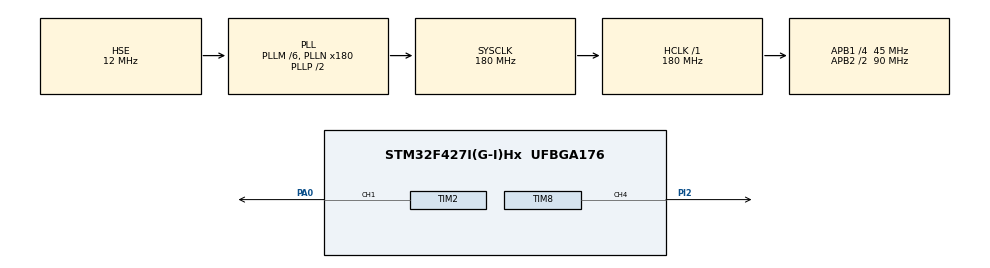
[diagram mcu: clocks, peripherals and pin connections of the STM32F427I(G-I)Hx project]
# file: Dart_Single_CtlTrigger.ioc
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Mcu.Family=STM32F4
Mcu.Name=STM32F427I(G-I)Hx
Mcu.Package=UFBGA176
NVIC.PriorityGroup=NVIC_PRIORITYGROUP_4
NVIC.TIM4_IRQn=true\:15\:0\:false\:false\:true\:false\:true\:true
NVIC.TimeBase=TIM4_IRQn
NVIC.TimeBaseIP=TIM4
PA0/WKUP.Signal=S_TIM2_CH1_ETR
PA13.Mode=Serial_Wire
PA13.Signal=SYS_JTMS-SWDIO
PA14.Mode=Serial_Wire
PA14.Signal=SYS_JTCK-SWCLK
PC14/OSC32_IN.Mode=LSE-External-Oscillator
PC14/OSC32_IN.Signal=RCC_OSC32_IN
PC15/OSC32_OUT.Mode=LSE-External-Oscillator
PC15/OSC32_OUT.Signal=RCC_OSC32_OUT
PH0/OSC_IN.Mode=HSE-External-Oscillator
PH0/OSC_IN.Signal=RCC_OSC_IN
PH1/OSC_OUT.Mode=HSE-External-Oscillator
PH1/OSC_OUT.Signal=RCC_OSC_OUT
PI2.Signal=S_TIM8_CH4
ProjectManager.HeapSize=0x200
ProjectManager.StackSize=0x400
ProjectManager.TargetToolchain=MDK-ARM V5.32
RCC.48MHZClocksFreq_Value=90000000
RCC.AHBFreq_Value=180000000
RCC.APB1CLKDivider=RCC_HCLK_DIV4
RCC.APB1Freq_Value=45000000
RCC.APB1TimFreq_Value=90000000
RCC.APB2CLKDivider=RCC_HCLK_DIV2
RCC.APB2Freq_Value=90000000
RCC.APB2TimFreq_Value=180000000
RCC.CortexFreq_Value=180000000
RCC.HCLKFreq_Value=180000000
RCC.HSE_VALUE=12000000
RCC.HSI_VALUE=16000000
RCC.PLLM=6
RCC.PLLN=180
RCC.PLLSourceVirtual=RCC_PLLSOURCE_HSE
RCC.SYSCLKFreq_VALUE=180000000
RCC.SYSCLKSource=RCC_SYSCLKSOURCE_PLLCLK
RCC.VCOOutputFreq_Value=360000000
SH.S_TIM2_CH1_ETR.0=TIM2_CH1,PWM Generation1 CH1
SH.S_TIM8_CH4.0=TIM8_CH4,PWM Generation4 CH4
TIM2.AutoReloadPreload=TIM_AUTORELOAD_PRELOAD_ENABLE
TIM2.Channel-PWM\ Generation1\ CH1=TIM_CHANNEL_1
TIM2.Period=20000 - 1
TIM2.Prescaler=180 - 1
TIM2.Pulse-PWM\ Generation1\ CH1=2500
TIM8.AutoReloadPreload=TIM_AUTORELOAD_PRELOAD_ENABLE
TIM8.Channel-PWM\ Generation4\ CH4=TIM_CHANNEL_4
TIM8.Period=20000 - 1
TIM8.Prescaler=180 - 1
TIM8.Pulse-PWM\ Generation4\ CH4=500
VP_SYS_VS_tim4.Mode=TIM4
VP_TIM2_VS_ClockSourceINT.Mode=Internal
VP_TIM8_VS_ClockSourceINT.Mode=Internal
board=custom

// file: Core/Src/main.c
/* USER CODE BEGIN Header */
/**
  ******************************************************************************
  * @file           : main.c
  * @brief          : Main program body
  ******************************************************************************
  * @attention
  *
  * Copyright (c) 2026 STMicroelectronics.
  * All rights reserved.
  *
  * This software is licensed under terms that can be found in the LICENSE file
  * in the root directory of this software component.
  * If no LICENSE file comes with this software, it is provided AS-IS.
  *
  ******************************************************************************
  */
/* USER CODE END Header */
#include "main.h"
#include "tim.h"
#include "gpio.h"

void SystemClock_Config(void);

int main(void)
{

  /* MCU Configuration--------------------------------------------------------*/

  /* Reset of all peripherals, Initializes the Flash interface and the Systick. */

  HAL_Init();

  /* Configure the system clock */
  SystemClock_Config();

  /* Initialize all configured peripherals */
  MX_GPIO_Init();
  MX_TIM2_Init();
  MX_TIM8_Init();
  /* USER CODE BEGIN 2 */
	HAL_TIM_Base_Start(&htim8);
  HAL_TIM_PWM_Start(&htim8, TIM_CHANNEL_4);
	HAL_Delay(500);
  // __HAL_TIM_SetCompare(&htim8, TIM_CHANNEL_4, 2500); // 直接复位
	// HAL_Delay(1000);
	// __HAL_TIM_SetCompare(&htim8, TIM_CHANNEL_4, 500);
	// HAL_Delay(2000);
  /* USER CODE END 2 */

  /* Infinite loop */
  /* USER CODE BEGIN WHILE */
	uint16_t a = 500;
	uint16_t b = 1200;
	uint16_t c = 1200;
  while (1)
  {
		a = a + 100;
		__HAL_TIM_SetCompare(&htim8, TIM_CHANNEL_4, b);

	  HAL_Delay(1000);

		__HAL_TIM_SetCompare(&htim8, TIM_CHANNEL_4, c);
		HAL_Delay(1000);
//		if(a >= 2500)
//		{
//			a = 500; // notes；新释放状态 1500，新绷紧状态2500
//		}

    /* USER CODE END WHILE */

  }
}

void SystemClock_Config(void)
{
  RCC_OscInitTypeDef RCC_OscInitStruct = {0};
  RCC_ClkInitTypeDef RCC_ClkInitStruct = {0};

  /** Configure the main internal regulator output voltage
  */
  __HAL_RCC_PWR_CLK_ENABLE();
  __HAL_PWR_VOLTAGESCALING_CONFIG(PWR_REGULATOR_VOLTAGE_SCALE1);

  /** Initializes the RCC Oscillators according to the specified parameters
  * in the RCC_OscInitTypeDef structure.
  */
  RCC_OscInitStruct.OscillatorType = RCC_OSCILLATORTYPE_HSE;
  RCC_OscInitStruct.HSEState = RCC_HSE_ON;
  RCC_OscInitStruct.PLL.PLLState = RCC_PLL_ON;
  RCC_OscInitStruct.PLL.PLLSource = RCC_PLLSOURCE_HSE;
  RCC_OscInitStruct.PLL.PLLM = 6;
  RCC_OscInitStruct.PLL.PLLN = 180;
  RCC_OscInitStruct.PLL.PLLP = RCC_PLLP_DIV2;
  RCC_OscInitStruct.PLL.PLLQ = 4;
  if (HAL_RCC_OscConfig(&RCC_OscInitStruct) != HAL_OK)
  {
    Error_Handler();
  }

  /** Activate the Over-Drive mode
  */
  if (HAL_PWREx_EnableOverDrive() != HAL_OK)
  {
    Error_Handler();
  }

  /** Initializes the CPU, AHB and APB buses clocks
  */
  RCC_ClkInitStruct.ClockType = RCC_CLOCKTYPE_HCLK|RCC_CLOCKTYPE_SYSCLK
                              |RCC_CLOCKTYPE_PCLK1|RCC_CLOCKTYPE_PCLK2;
  RCC_ClkInitStruct.SYSCLKSource = RCC_SYSCLKSOURCE_PLLCLK;
  RCC_ClkInitStruct.AHBCLKDivider = RCC_SYSCLK_DIV1;
  RCC_ClkInitStruct.APB1CLKDivider = RCC_HCLK_DIV4;
  RCC_ClkInitStruct.APB2CLKDivider = RCC_HCLK_DIV2;

  if (HAL_RCC_ClockConfig(&RCC_ClkInitStruct, FLASH_LATENCY_5) != HAL_OK)
  {
    Error_Handler();
  }
}

void HAL_TIM_PeriodElapsedCallback(TIM_HandleTypeDef *htim)
{
  if (htim->Instance == TIM4)
  {
    HAL_IncTick();
  }
}

void Error_Handler(void)
{
  __disable_irq();
  while (1)
  {
  }
}
